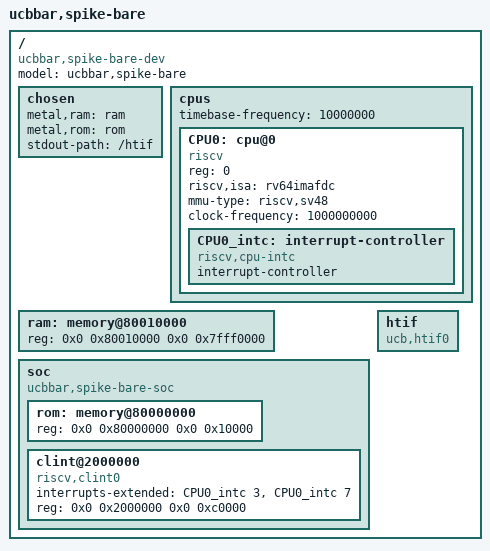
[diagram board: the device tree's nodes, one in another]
/dts-v1/;

/ {
  #address-cells = <2>;
  #size-cells = <2>;
  compatible = "ucbbar,spike-bare-dev";
  model = "ucbbar,spike-bare";
  chosen {
    metal,ram = <&ram>;
    metal,rom = <&rom>;
    stdout-path = "/htif";
  };
  cpus {
    #address-cells = <1>;
    #size-cells = <0>;
    timebase-frequency = <10000000>;
    CPU0: cpu@0 {
      device_type = "cpu";
      reg = <0>;
      status = "okay";
      compatible = "riscv";
      riscv,isa = "rv64imafdc";
      mmu-type = "riscv,sv48";
      clock-frequency = <1000000000>;
      CPU0_intc: interrupt-controller {
        #interrupt-cells = <1>;
        interrupt-controller;
        compatible = "riscv,cpu-intc";
      };
    };
  };
  ram: memory@80010000 {
    device_type = "memory";
    reg = <0x0 0x80010000 0x0 0x7fff0000>;
  };
  soc {
    #address-cells = <2>;
    #size-cells = <2>;
    compatible = "ucbbar,spike-bare-soc", "simple-bus";
    ranges;
    rom: memory@80000000 {
      device_type = "memory";
      reg = <0x0 0x80000000 0x0 0x10000>;
    };
    clint@2000000 {
      compatible = "riscv,clint0";
      interrupts-extended = <&CPU0_intc 3 &CPU0_intc 7 >;
      reg = <0x0 0x2000000 0x0 0xc0000>;
    };
  };
  htif {
    compatible = "ucb,htif0";
  };
};
